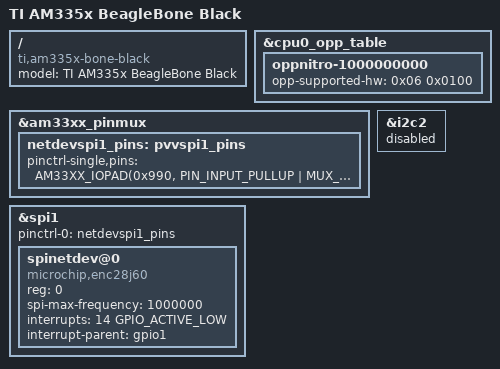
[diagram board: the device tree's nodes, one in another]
/*
 * Copyright (C) 2012 Texas Instruments Incorporated - http://www.ti.com/
 *
 * This program is free software; you can redistribute it and/or modify
 * it under the terms of the GNU General Public License version 2 as
 * published by the Free Software Foundation.
 */
/dts-v1/;

#include "am33xx.dtsi"
#include "am335x-bone-common.dtsi"
#include "am335x-boneblack-common.dtsi"

/ {
	model = "TI AM335x BeagleBone Black";
	compatible = "ti,am335x-bone-black", "ti,am335x-bone", "ti,am33xx";
};

&cpu0_opp_table {
	/*
	 * All PG 2.0 silicon may not support 1GHz but some of the early
	 * BeagleBone Blacks have PG 2.0 silicon which is guaranteed
	 * to support 1GHz OPP so enable it for PG 2.0 on this board.
	 */
	oppnitro-1000000000 {
		opp-supported-hw = <0x06 0x0100>;
	};
};

&am33xx_pinmux {
	netdevspi1_pins: pvvspi1_pins {
		pinctrl-single,pins = <
			/* MCASP0_ACLKX GPIO3_14 P9-31 SPI1_SCLK */
			AM33XX_IOPAD(0x990, PIN_INPUT_PULLUP | MUX_MODE3)

			/* MCASP0_FSX GPIO3_15 P9-29 SPI1_DO */
			AM33XX_IOPAD(0x994, PIN_INPUT_PULLUP | MUX_MODE3)

			/* MCASP0_AXR0 GPIO3_16 P9-30 SPI1_D1 */
			AM33XX_IOPAD(0x998, PIN_OUTPUT_PULLUP | MUX_MODE3)

			/* MCASP0_AHCLKR GPIO3_17 P9-28 SPI1_CS0 */
			AM33XX_IOPAD(0x99C, PIN_OUTPUT_PULLUP | MUX_MODE3)

			/* gpmc_ad15 gpio1_14 P8-16 GPIO_INT */
			AM33XX_IOPAD(0x838, PIN_INPUT | MUX_MODE7)
		>;
	};
};

&i2c2 {
	status					= "disabled";
};

&spi1 {
	#address-cells				= <1>;
	#size-cells				= <0>;
	status					= "okay";
	pinctrl-names = "default";
	pinctrl-0 = <&netdevspi1_pins>;

	spinetdev@0{
		compatible			= "microchip,enc28j60";
		reg				= <0>;
		spi-max-frequency		= <1000000>;
		interrupts = <14 GPIO_ACTIVE_LOW>;
		interrupt-parent = <&gpio1>;
	};
};
